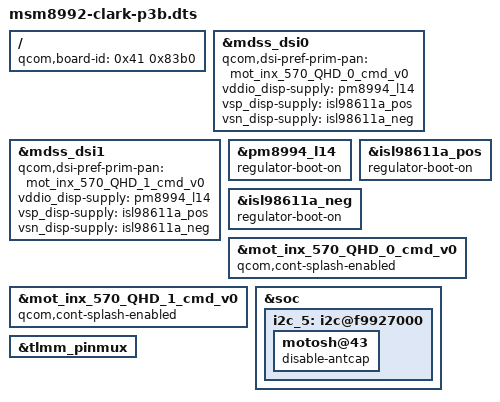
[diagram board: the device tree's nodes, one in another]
/* Copyright (c) 2015, Motorola Mobility LLC. All rights reserved.
 *
 * This program is free software; you can redistribute it and/or modify
 * it under the terms of the GNU General Public License version 2 and
 * only version 2 as published by the Free Software Foundation.
 *
 * This program is distributed in the hope that it will be useful,
 * but WITHOUT ANY WARRANTY; without even the implied warranty of
 * MERCHANTABILITY or FITNESS FOR A PARTICULAR PURPOSE.  See the
 * GNU General Public License for more details.
 */


/dts-v1/;

#include "msm8992-clark.dtsi"
#include "dsi-panel-mot-inx-570-QHD-cmd.dtsi"

/ {
	qcom,board-id = <0x41 0x83b0>;
};

&mdss_dsi0 {
	qcom,dsi-pref-prim-pan = <&mot_inx_570_QHD_0_cmd_v0>;
	vddio_disp-supply = <&pm8994_l14>;
	vsp_disp-supply = <&isl98611a_pos>;
	vsn_disp-supply = <&isl98611a_neg>;

	#include"dsi-panel-mot-inx-570-QHD-supplies.dtsi"
};

&mdss_dsi1 {
	qcom,dsi-pref-prim-pan = <&mot_inx_570_QHD_1_cmd_v0>;
	vddio_disp-supply = <&pm8994_l14>;
	vsp_disp-supply = <&isl98611a_pos>;
	vsn_disp-supply = <&isl98611a_neg>;

	#include"dsi-panel-mot-inx-570-QHD-supplies.dtsi"
};

&pm8994_l14 {
	regulator-boot-on;
};

&isl98611a_pos {
	regulator-boot-on;
	/delete-property/ regulator-always-on;
};

&isl98611a_neg {
	regulator-boot-on;
	/delete-property/ regulator-always-on;
};

&mot_inx_570_QHD_0_cmd_v0 {
	qcom,cont-splash-enabled;
};

&mot_inx_570_QHD_1_cmd_v0 {
	qcom,cont-splash-enabled;
};

&soc {
	/delete-node/ cycapsense_prog;
	i2c_5: i2c@f9927000 {
		motosh@43 {
			disable-antcap;
			/delete-property/ antcap_cfg;
		};
	};
};

&tlmm_pinmux {
	/delete-node/ cycapsense;
	/delete-node/ cycapsense_data;
};
